VERSION ""

NS_ :

BS_:

BU_: FS_Datalogger

BO_ 1877 FS_Datalogger_Reserved_6: 8 Vector__XXX

BO_ 1876 FS_Datalogger_Reserved_5: 8 Vector__XXX

BO_ 1875 FS_Datalogger_Reserved_4: 8 Vector__XXX

BO_ 1874 FS_Datalogger_Reserved_3: 8 Vector__XXX

BO_ 1873 FS_Datalogger_Reserved_2: 8 Vector__XXX

BO_ 1872 FS_Datalogger_Reserved_1: 8 Vector__XXX

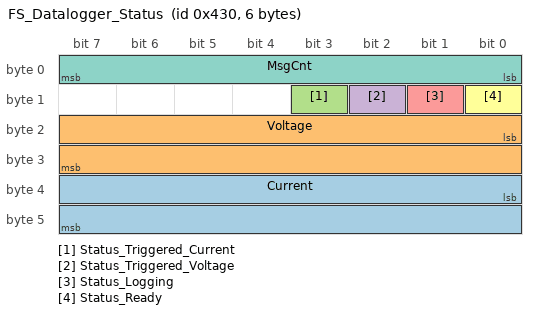
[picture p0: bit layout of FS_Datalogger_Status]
BO_ 1072 FS_Datalogger_Status: 6 FS_Datalogger
 SG_ Current : 32|16@1+ (64,0) [0|4194240] "mA" Vector__XXX
 SG_ Voltage : 16|16@1+ (16,0) [0|1048560] "mV" Vector__XXX
 SG_ Status_Triggered_Current : 11|1@1- (1,0) [0|0] "" Vector__XXX
 SG_ Status_Triggered_Voltage : 10|1@1- (1,0) [0|0] "" Vector__XXX
 SG_ Status_Logging : 9|1@1- (1,0) [0|0] "" Vector__XXX
 SG_ Status_Ready : 8|1@1- (1,0) [0|0] "" Vector__XXX
 SG_ MsgCnt : 0|8@1+ (1,0) [0|255] "" Vector__XXX

BA_DEF_  "BusType" STRING ;
BA_DEF_DEF_  "BusType" "CAN";
